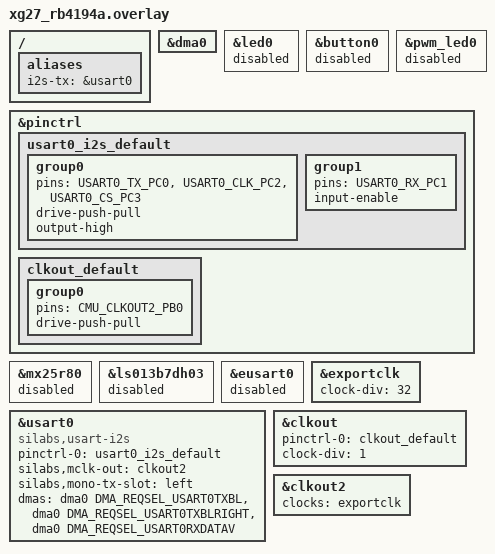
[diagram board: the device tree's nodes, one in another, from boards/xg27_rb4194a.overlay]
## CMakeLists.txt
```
# LOCAL ONLY — do not push.
cmake_minimum_required(VERSION 3.20.0)
find_package(Zephyr REQUIRED HINTS $ENV{ZEPHYR_BASE})
project(i2s_output_mclk_loop)

set(FRAME_CLK_HZ 16000 CACHE STRING "I2S WS / frame clock (Hz)")
set(WORD_SIZE 16 CACHE STRING "I2S word size (16 or 32)")
set(CHANNEL_MODE mono_left CACHE STRING "stereo | mono_left | mono_right")

target_sources(app PRIVATE src/main.c)
target_compile_definitions(app PRIVATE
  FRAME_CLK_HZ=${FRAME_CLK_HZ}
  WORD_SIZE=${WORD_SIZE}
)

if(CHANNEL_MODE STREQUAL "mono_left")
  target_compile_definitions(app PRIVATE I2S_CHANNELS=1)
elseif(CHANNEL_MODE STREQUAL "mono_right")
  target_compile_definitions(app PRIVATE I2S_CHANNELS=1)
  message(WARNING "mono_right also needs silabs,mono-tx-slot = \"right\" in the overlay")
elseif(CHANNEL_MODE STREQUAL "stereo")
  target_compile_definitions(app PRIVATE I2S_CHANNELS=2)
else()
  message(FATAL_ERROR "CHANNEL_MODE must be stereo, mono_left, or mono_right")
endif()
```

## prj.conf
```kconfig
CONFIG_I2S=y
CONFIG_DMA=y
```

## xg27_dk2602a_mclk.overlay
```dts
/*
 * LOCAL ONLY — do not push. EXTRA overlay for samples/drivers/i2s/output.
 *
 * Adds CMU CLKOUT2 MCLK on PB0 (EXP7): EXPORTCLK / 32 ≈ 2.4 MHz.
 * Base I2S pins come from sample boards/xg27_dk2602a.overlay
 * (PC0 TX, PC2 BCLK, PB2 WS).
 *
 * Probe: MCLK=EXP7, BCLK=EXP8, WS=EXP10, SD=EXP4. Keep PC7 (mic enable) LOW.
 */

#include <zephyr/dt-bindings/pinctrl/silabs/xg27-pinctrl.h>

&usart0 {
	silabs,mclk-out = <&clkout2>;
};

&pinctrl {
	clkout_default: clkout_default {
		group0 {
			pins = <CMU_CLKOUT2_PB0>;
			drive-push-pull;
		};
	};
};

&exportclk {
	clock-div = <32>;
};

&clkout {
	pinctrl-0 = <&clkout_default>;
	pinctrl-names = "default";
	clock-div = <1>;
	status = "okay";
};

&clkout2 {
	clocks = <&exportclk>;
	status = "okay";
};
```

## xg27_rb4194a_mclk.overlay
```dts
/*
 * LOCAL ONLY — do not push. EXTRA overlay for samples/drivers/i2s/output.
 *
 * Adds CMU CLKOUT2 MCLK on PB0 (EXP7): EXPORTCLK / 32 ≈ 2.4 MHz.
 * Base I2S pins come from sample boards/xg27_rb4194a.overlay
 * (PC0 TX, PC2 BCLK, PC3 WS).
 *
 * PB0 is shared with LED0 / button0 — disable those so CLKOUT owns the pin.
 * Probe: MCLK=EXP7, BCLK=EXP8, WS=EXP10, SD=EXP4.
 */

#include <zephyr/dt-bindings/pinctrl/silabs/xg27-pinctrl.h>

&led0 {
	status = "disabled";
};

&button0 {
	status = "disabled";
};

&pwm_led0 {
	status = "disabled";
};

&usart0 {
	silabs,mclk-out = <&clkout2>;
};

&pinctrl {
	clkout_default: clkout_default {
		group0 {
			pins = <CMU_CLKOUT2_PB0>;
			drive-push-pull;
		};
	};
};

&exportclk {
	clock-div = <32>;
};

&clkout {
	pinctrl-0 = <&clkout_default>;
	pinctrl-names = "default";
	clock-div = <1>;
	status = "okay";
};

&clkout2 {
	clocks = <&exportclk>;
	status = "okay";
};
```

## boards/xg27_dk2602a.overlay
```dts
/*
 * LOCAL: USART0 I2S + CLKOUT2 MCLK on DK2602A.
 * TX PC0/EXP4, BCLK PC2/EXP8, WS PB2/EXP10, MCLK PB0/EXP7 (~2.4 MHz).
 */

#include <zephyr/dt-bindings/pinctrl/silabs/xg27-pinctrl.h>
#include <zephyr/dt-bindings/dma/silabs/xg27-dma.h>

&dma0 {
	status = "okay";
};

/ {
	aliases {
		i2s-tx = &usart0;
	};
};

&pinctrl {
	usart0_i2s_default: usart0_i2s_default {
		group0 {
			pins = <USART0_TX_PC0>, <USART0_CLK_PC2>, <USART0_CS_PB2>;
			drive-push-pull;
			output-high;
		};

		group1 {
			pins = <USART0_RX_PC1>;
			input-enable;
		};
	};

	clkout_default: clkout_default {
		group0 {
			pins = <CMU_CLKOUT2_PB0>;
			drive-push-pull;
		};
	};
};

/delete-node/ &mx25r80;

&usart0 {
	compatible = "silabs,usart-i2s";
	/delete-property/ cs-gpios;
	#address-cells = <1>;
	#size-cells = <0>;
	status = "okay";
	pinctrl-0 = <&usart0_i2s_default>;
	pinctrl-names = "default";
	silabs,mclk-out = <&clkout2>;
	silabs,mono-tx-slot = "left";
	dmas = <&dma0 DMA_REQSEL_USART0TXBL>,
	       <&dma0 DMA_REQSEL_USART0TXBLRIGHT>,
	       <&dma0 DMA_REQSEL_USART0RXDATAV>;
	dma-names = "txbl", "txblright", "rx";
};

&exportclk {
	clock-div = <32>;
};

&clkout {
	pinctrl-0 = <&clkout_default>;
	pinctrl-names = "default";
	clock-div = <1>;
	status = "okay";
};

&clkout2 {
	clocks = <&exportclk>;
	status = "okay";
};
```

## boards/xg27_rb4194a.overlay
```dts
/*
 * LOCAL: USART0 I2S + CLKOUT2 MCLK on RB4194A.
 * TX PC0/EXP4, BCLK PC2/EXP8, WS PC3/EXP10, MCLK PB0/EXP7 (~2.4 MHz).
 * LED0/button0 disabled (share PB0).
 */

#include <zephyr/dt-bindings/pinctrl/silabs/xg27-pinctrl.h>
#include <zephyr/dt-bindings/dma/silabs/xg27-dma.h>

&dma0 {
	status = "okay";
};

/ {
	aliases {
		i2s-tx = &usart0;
		/delete-property/ spi-flash0;
	};
};

&led0 {
	status = "disabled";
};

&button0 {
	status = "disabled";
};

&pwm_led0 {
	status = "disabled";
};

&pinctrl {
	usart0_i2s_default: usart0_i2s_default {
		group0 {
			pins = <USART0_TX_PC0>, <USART0_CLK_PC2>, <USART0_CS_PC3>;
			drive-push-pull;
			output-high;
		};

		group1 {
			pins = <USART0_RX_PC1>;
			input-enable;
		};
	};

	clkout_default: clkout_default {
		group0 {
			pins = <CMU_CLKOUT2_PB0>;
			drive-push-pull;
		};
	};
};

&mx25r80 {
	status = "disabled";
};

&ls013b7dh03 {
	status = "disabled";
};

&eusart0 {
	status = "disabled";
};

&usart0 {
	compatible = "silabs,usart-i2s";
	#address-cells = <1>;
	#size-cells = <0>;
	status = "okay";
	pinctrl-0 = <&usart0_i2s_default>;
	pinctrl-names = "default";
	silabs,mclk-out = <&clkout2>;
	silabs,mono-tx-slot = "left";
	dmas = <&dma0 DMA_REQSEL_USART0TXBL>,
	       <&dma0 DMA_REQSEL_USART0TXBLRIGHT>,
	       <&dma0 DMA_REQSEL_USART0RXDATAV>;
	dma-names = "txbl", "txblright", "rx";
};

&exportclk {
	clock-div = <32>;
};

&clkout {
	pinctrl-0 = <&clkout_default>;
	pinctrl-names = "default";
	clock-div = <1>;
	status = "okay";
};

&clkout2 {
	clocks = <&exportclk>;
	status = "okay";
};
```

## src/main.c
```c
/*
 * LOCAL ONLY — looping 1 kHz sine for scope (MCLK + I2S).
 * Default: 16 kHz, 16-bit, mono left (CMake FRAME_CLK_HZ / WORD_SIZE / CHANNEL_MODE).
 */

#include <stdio.h>
#include <string.h>
#include <zephyr/kernel.h>
#include <zephyr/drivers/i2s.h>
#include <zephyr/sys/iterable_sections.h>

#ifndef FRAME_CLK_HZ
#define FRAME_CLK_HZ 16000
#endif
#ifndef WORD_SIZE
#define WORD_SIZE 16
#endif
#ifndef I2S_CHANNELS
#define I2S_CHANNELS 1
#endif

#define NUM_BLOCKS 8

/*
 * One period of 1 kHz at 16 kHz (16 samples). Other FRAME_CLK_HZ values
 * still play this table, so tone = 1 kHz * (FRAME_CLK_HZ / 16000).
 */
static const int16_t sine_1khz_16k[] = {
	     0,  12540,  23170,  30274,  32767,  30274,  23170,  12540,
	     0, -12540, -23170, -30274, -32767, -30274, -23170, -12540,
};

#define SAMPLE_NO ARRAY_SIZE(sine_1khz_16k)
#define FRAME_BYTES ((WORD_SIZE / 8) * I2S_CHANNELS)
#define BLOCK_SIZE  (SAMPLE_NO * FRAME_BYTES)

static void fill_buf(void *tx_block)
{
	if (WORD_SIZE == 16 && I2S_CHANNELS == 1) {
		memcpy(tx_block, sine_1khz_16k, sizeof(sine_1khz_16k));
		return;
	}

	if (WORD_SIZE == 16 && I2S_CHANNELS == 2) {
		int16_t *dst = tx_block;

		for (int i = 0; i < SAMPLE_NO; i++) {
			dst[2 * i] = sine_1khz_16k[i];
			dst[2 * i + 1] = 0;
		}
		return;
	}

	/* 32-bit slot: 16-bit sine in low half */
	if (WORD_SIZE == 32 && I2S_CHANNELS == 1) {
		int32_t *dst = tx_block;

		for (int i = 0; i < SAMPLE_NO; i++) {
			dst[i] = (int32_t)sine_1khz_16k[i];
		}
		return;
	}

	int32_t *dst = tx_block;

	for (int i = 0; i < SAMPLE_NO; i++) {
		dst[2 * i] = (int32_t)sine_1khz_16k[i];
		dst[2 * i + 1] = 0;
	}
}

static char __aligned(WB_UP(32))
	_k_mem_slab_buf_tx_0_mem_slab[(NUM_BLOCKS) * WB_UP(BLOCK_SIZE)];

static STRUCT_SECTION_ITERABLE(k_mem_slab, tx_0_mem_slab) =
	Z_MEM_SLAB_INITIALIZER(tx_0_mem_slab, _k_mem_slab_buf_tx_0_mem_slab,
			       WB_UP(BLOCK_SIZE), NUM_BLOCKS);

int main(void)
{
	struct i2s_config i2s_cfg;
	const struct device *dev_i2s = DEVICE_DT_GET(DT_ALIAS(i2s_tx));
	int ret;
	bool started = false;

	if (!device_is_ready(dev_i2s)) {
		printf("I2S device not ready\n");
		return -ENODEV;
	}

	i2s_cfg.word_size = WORD_SIZE;
	i2s_cfg.channels = I2S_CHANNELS;
	i2s_cfg.format = I2S_FMT_DATA_FORMAT_I2S;
	i2s_cfg.frame_clk_freq = FRAME_CLK_HZ;
	i2s_cfg.block_size = BLOCK_SIZE;
	i2s_cfg.timeout = 2000;
	i2s_cfg.options = I2S_OPT_FRAME_CLK_CONTROLLER | I2S_OPT_BIT_CLK_CONTROLLER;
	i2s_cfg.mem_slab = &tx_0_mem_slab;

	ret = i2s_configure(dev_i2s, I2S_DIR_TX, &i2s_cfg);
	if (ret < 0) {
		printf("Failed to configure I2S stream (%d)\n", ret);
		return ret;
	}

	printf("I2S loop 1kHz sine: WS=%u Hz, %u-bit, ch=%u, BCLK~%u Hz\n",
	       FRAME_CLK_HZ, WORD_SIZE, I2S_CHANNELS,
	       FRAME_CLK_HZ * 2U * WORD_SIZE);

	for (;;) {
		void *mem;

		ret = k_mem_slab_alloc(&tx_0_mem_slab, &mem, K_FOREVER);
		if (ret < 0) {
			printf("slab alloc failed\n");
			return ret;
		}
		fill_buf(mem);

		ret = i2s_write(dev_i2s, mem, BLOCK_SIZE);
		if (ret < 0) {
			printf("i2s_write failed (%d)\n", ret);
			k_mem_slab_free(&tx_0_mem_slab, mem);
			return ret;
		}

		if (!started) {
			ret = i2s_trigger(dev_i2s, I2S_DIR_TX, I2S_TRIGGER_START);
			if (ret < 0) {
				printf("I2S START failed (%d)\n", ret);
				return ret;
			}
			started = true;
		}
	}
}
```
